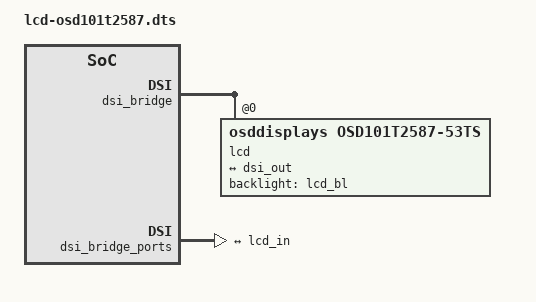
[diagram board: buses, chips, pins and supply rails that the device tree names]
// SPDX-License-Identifier: GPL-2.0
/*
 * Copyright (C) 2019 Texas Instruments Incorporated - http://www.ti.com/
 */

/dts-v1/;
/plugin/;

&dsi_bridge {
	#address-cells = <1>;
	#size-cells = <0>;

	lcd: display {
		compatible = "osddisplays,osd101t2587-53ts";
		reg = <0>;

		label = "lcd";

		backlight = <&lcd_bl>;

		port {
			lcd_in: endpoint {
				remote-endpoint = <&dsi_out>;
			};
		};
	};
};

&dsi_bridge_ports {
	#address-cells = <1>;
	#size-cells = <0>;

	port@1 {
		reg = <1>;
		dsi_out: endpoint {
			remote-endpoint = <&lcd_in>;
		};
	};
};
